# cslr_ms_001 register map
Vendor: Texas Instruments
Peripheral module from a debugger description file.
Registers are 32-bit, access not given, reset 0x0 unless marked. A register's access mark holds for its fields unless they carry their own. Offsets are as the file gives them; lines under a group give offsets from that group; [hi:lo] are bit positions; {n}, {i} and the like mark numbered series; 'fields as' and 'values as' point back to an identical list; <NAME> marks a mode.

## MS — Memory Stick
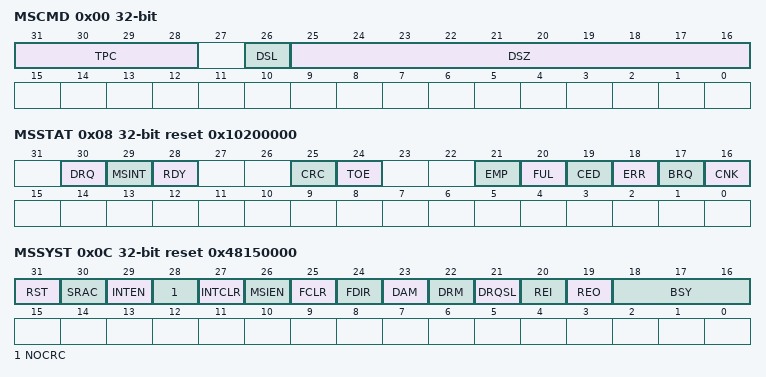
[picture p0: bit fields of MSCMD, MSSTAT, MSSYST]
0x00 MSCMD — MS Command Register
  [31:28] TPC rw — Transfer Protocol Code These bits designate the TPC Note: See MS specification for details on TPC
  [26] DSL rw — DSL (Data Select) This designates the data to be communicated with the Memory Stick.
    0=MSFIFO (Data is transmitted to and received using the internal FIFO); 1=MSEXTMEM (Data is transmitted to and received from the Memory Stick using an external memory)
  [25:16] DSZ rw — Transfer Data Size Transmit/receive data length, in bytes. The length can be set from 1byte to 1024bytes. When MSDSZ is 0, data size is set to 1024bytes. 0001 - 1byte 0002 - 2bytes . . 1023 - 1023bytes 0000 - 1024bytes
0x04 MSCDAT rw — MS Data Register
  [31:0] DATA — FIFO Data Buffer This register is used to access internal FIFO (32bytes). Minimum access unit to the FIFO is 8bytes(4bytes*2times) Host should access this register 2 times continously. When the CPU host reads data from FIFO or writes data to FIFO, it needs to monitor EMP and FUL bits in the status register MSSTAT. Condition of FIFO write (transmit): DRQ=1 and FUL=0. Condition of FIFO read (receive): DRQ=1 and EMP=0.
0x08 MSSTAT reset 0x10200000 — MS Status Register
  [30] DRQ ro — Data Request Interrupt Flag - Write sequence to Memory Stick 0: No data request 1: FIFO requires data (need to write transmit data) - Read sequence from Memory Stick 0: No data request 1: FIFO has data (need to read receive data)
  [29] MSINT ro — Memory Stick Interface Interrupt bit 0: No interrupt request received from Memory Stick 1: Interrupt request received from Memory Stick
  [28] RDY ro — Ready bit 0: Command receive disabled 1: Command receive enabled or protocol ended
  [25] CRC ro — CRC Error Bits 0: No CRC error 1: CRC error ocurred during data receive
  [24] TOE ro — Time Out Error bit 0: No time out error 1: RDY time out error
  [21] EMP ro — FIFO Empty 0: FIFO contains data 1: FIFO empty Note: This bit is cleared to 1 by writing '1' to System Register bit FCLR
  [20] FUL ro — FIFO Full 0: FIFO has empty spaces 1: FIFO full
  [19] CED ro — MS Command End 0: Command end is NOT indicated 1: Command end is indicated
  [18] ERR ro — MS Error 0: No Memory Stick errors 1: Memory Stick error is indicated
  [17] BRQ ro — MS Data Buffer Request 0: No data buffer request 1: Memory Stick data buffer request is indicated
  [16] CNK ro — MS Command No Acknowledge 0: Command acknowledge is indicated 1: Command no acknowledge is indicated from MS
0x0C MSSYST reset 0x48150000 — MS System Register
  [31] RST rw — Sync Reset 0: No sync reset is performed 1: Sync reset is performed
  [30] SRAC rw — Serial Access Mode 0: Parallel interface mode (Memory Stick Ver2.0) 1: Serial interface mode (Memory Stick Ver1.3)
  [29] INTEN rw — Interrupt Enable 0: Interrupt request disable 1: Interrupt request output to HOST enable
  [28] NOCRC rw — No CRC 0: CRC output on 1: CRC output off
  [27] INTCLR rw — Interrupt Clear 0: No interrupt clear 1: Interrupt to HOST is cleared
  [26] MSIEN rw — MS device Interrupt Enable 0: Interrupt Request from Memory Stick disabled 1: Interrupt Request from Memory Stick enabled
  [25] FCLR rw — FIFO Clear 0: FIFO clear disable 1: FIFO clear enable
  [24] FDIR rw — FIFO Direction 0: FIFO direction is set to (MS to FIFO to CPU) 1: FIFO direction is set to (CPU to FIFO to MS)
  [23] DAM rw — DMA Access Mode 0: DMA Access disable 1: DMA Access enable
  [22] DRM rw — DMA Data Request Mode;0:Level Mode;1:Edge Mode
  [21] DRQSL rw — Data Request Interrupt Enable 0: Interrupt is NOT generated when data request occurs 1: Interrupt is generated when data request occurs
  [20] REI rw — Rise Edge Input 0: MSDIO is latched at the falling edge of SCLK 1: MSDIO is latched at the rising edge of SCLK
  [19] REO rw — Rise Edge Output 0: MSPDO is latched at the falling edge of SCLK 1: MSPDO is latched at the rising edge of SCLK
  [18:16] BSY rw — Busy Count Initial value is set to 5 (BSY[2:0]=101). These bits set the RDY time-out time for the Memory Stick. The maximum BSY wait time until the RDY signal is output from the Memory Stick is set to (BSY setting value x 4 SCLK). However time-out detection is not performed when BSY=0.
